AUTOSAR XML (schema 00050)
package /Components
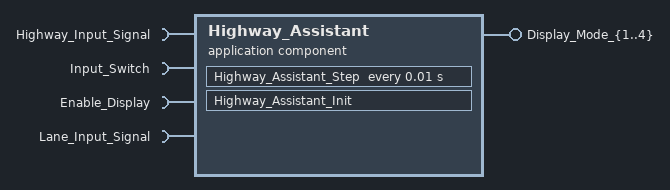
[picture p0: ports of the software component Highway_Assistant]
  application sw component type Highway_Assistant
    4 x require port:
      Highway_Input_Signal: nonqueued-receiver-com-spec{data-element=Highway_Input_Signal, init-value=0}, required-interface=Highway_Input_Signal
      Input_Switch: nonqueued-receiver-com-spec{data-element=Input_Switch, init-value=0}, required-interface=Input_Switch
      Enable_Display: nonqueued-receiver-com-spec{data-element=Enable_Display, init-value=0}, required-interface=Enable_Display
      Lane_Input_Signal: nonqueued-receiver-com-spec{data-element=Lane_Input_Signal, init-value=0}, required-interface=Lane_Input_Signal
    4 x provide port:
      Display_Mode_{1..4}: nonqueued-sender-com-spec{data-element=Display_Mode_{1..4}, init-value=0}, provided-interface=Display_Mode_{1..4}
    behavior Highway_Assistant_IB: handle-termination-and-restart=NO-SUPPORT
      timing event Event_Highway_Assistant_Step: start-on-event=Highway_Assistant_Step, period=0.01
      runnable Highway_Assistant_Init
      runnable Highway_Assistant_Step
        data-read-access:
          4 x access:
            IN_Enable_Display_Enable_Display: accessed-variable=Enable_Display.Enable_Display
            IN_Highway_Input_Signal_Highway_Input_Signal: accessed-variable=Highway_Input_Signal.Highway_Input_Signal
            IN_Input_Switch_Input_Switch: accessed-variable=Input_Switch.Input_Switch
            IN_Lane_Input_Signal_Lane_Input_Signal: accessed-variable=Lane_Input_Signal.Lane_Input_Signal
        data-write-access:
          4 x access:
            OUT_Display_Mode_{1..4}_Display_Mode_{1..4}: accessed-variable=Display_Mode_{1..4}.Display_Mode_{1..4}
